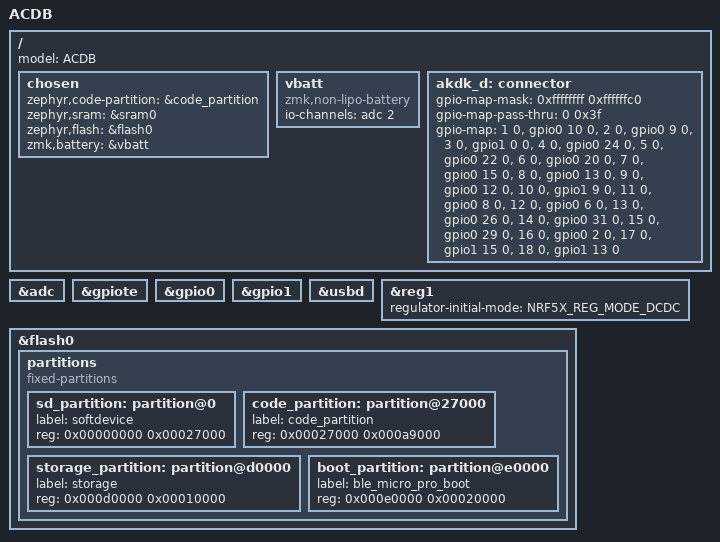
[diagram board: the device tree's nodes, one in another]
/*
 * Copyright (c) 2026 sekigon-gonnoc
 *
 * SPDX-License-Identifier: MIT
 */

/dts-v1/;

#include <nordic/nrf52840_qiaa.dtsi>
#include <common/nordic/nrf52840_uf2_boot_mode.dtsi>

/ {
    model = "ACDB";

    chosen {
        zephyr,code-partition = &code_partition;
        zephyr,sram = &sram0;
        zephyr,flash = &flash0;
        zmk,battery = &vbatt;
    };

    vbatt: vbatt {
        compatible = "zmk,non-lipo-battery";
        io-channels = <&adc 2>;
    };

	akdk_d: connector {
		#gpio-cells = <2>;
		gpio-map-mask = <0xffffffff 0xffffffc0>;
		gpio-map-pass-thru = <0 0x3f>;
		gpio-map
			= <1 0 &gpio0 10 0>
			, <2 0 &gpio0 9 0>	
			, <3 0 &gpio1 0 0>	
			, <4 0 &gpio0 24 0>
			, <5 0 &gpio0 22 0>
			, <6 0 &gpio0 20 0>
			, <7 0 &gpio0 15 0>
			, <8 0 &gpio0 13 0>
			, <9 0 &gpio0 12 0>	
			, <10 0 &gpio1 9 0>	
			, <11 0 &gpio0 8 0>
			, <12 0 &gpio0 6 0>
			, <13 0 &gpio0 26 0>
			, <14 0 &gpio0 31 0>
			, <15 0 &gpio0 29 0>
			, <16 0 &gpio0 2 0>
			, <17 0 &gpio1 15 0>
			, <18 0 &gpio1 13 0>
			;
	};
};

&adc {
    status = "okay";
};

&gpiote {
    status = "okay";
};

&gpio0 {
    status = "okay";
};

&gpio1 {
    status = "okay";
};

zephyr_udc0: &usbd {
    status = "okay";
};

&reg1 {
    regulator-initial-mode = <NRF5X_REG_MODE_DCDC>;
};

&flash0 {
    partitions {
        compatible = "fixed-partitions";
        #address-cells = <1>;
        #size-cells = <1>;

        sd_partition: partition@0 {
            label = "softdevice";
            reg = <0x00000000 0x00027000>;
        };

        /* 32 KB were given back to settings (below): the largest image built
         * for this board is about 540 KB, against 676 KB here. */
        code_partition: partition@27000 {
            label = "code_partition";
            reg = <0x00027000 0x000a9000>;
        };

        /* 64 KB. The 32 KB this started with ran out on ClickBoard ErgoTrack:
         * three layers of keymap, the bonds, sixty-odd trackpad settings, two
         * ripple maps and the macro, combo and tap-dance slots filled NVS,
         * after which every new save was silently refused -- a setting that
         * took effect until the next reboot and then came back as it was.
         * CONFIG_SETTINGS_NVS_SECTOR_COUNT (acdb_defconfig) must cover the
         * whole partition or the extra space goes unused. Changing this moves
         * the settings area, so a build with it needs a settings reset. */
        storage_partition: partition@d0000 {
            label = "storage";
            reg = <0x000d0000 0x00010000>;
        };

        boot_partition: partition@e0000 {
            label = "ble_micro_pro_boot";
            reg = <0x000e0000 0x00020000>;
        };
    };
};
